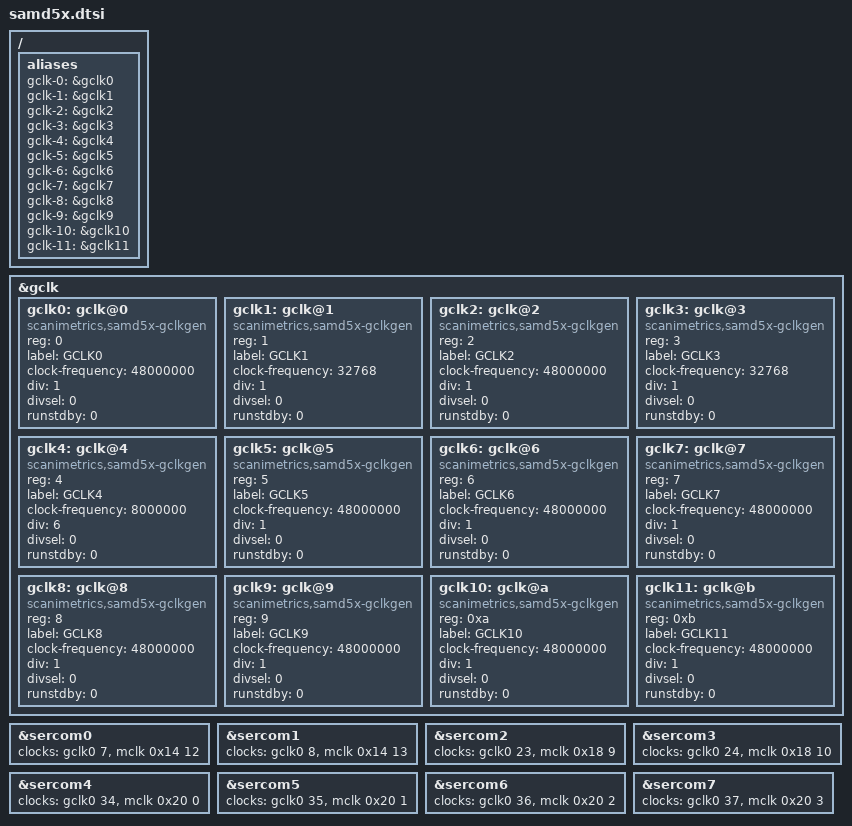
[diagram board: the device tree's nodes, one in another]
/*
 * Copyright (c) 2020 Scanimetics Inc.
 *
 * SPDX-License-Identifier: Apache-2.0
 */

#include <atmel/samd5x.dtsi>

/ {
	aliases {
		gclk-0 = &gclk0;
		gclk-1 = &gclk1;
		gclk-2 = &gclk2;
		gclk-3 = &gclk3;
		gclk-4 = &gclk4;
		gclk-5 = &gclk5;
		gclk-6 = &gclk6;
		gclk-7 = &gclk7;
		gclk-8 = &gclk8;
		gclk-9 = &gclk9;
		gclk-10 = &gclk10;
		gclk-11 = &gclk11;
	};
};

&gclk {
	#address-cells = <1>;
	#size-cells = <0>;

	gclk0: gclk@0 {
		compatible = "scanimetrics,samd5x-gclkgen";
		#clock-cells = <1>;
		reg = <0>;
		label = "GCLK0";
		clock-frequency = <48000000>;
		div = <1>;
		divsel = <0>;
		runstdby = <0>;
	};

	gclk1: gclk@1 {
		compatible = "scanimetrics,samd5x-gclkgen";
		#clock-cells = <1>;
		reg = <1>;
		label = "GCLK1";
		clock-frequency = <32768>;
		div = <1>;
		divsel = <0>;
		runstdby = <0>;
	};

	gclk2: gclk@2 {
		compatible = "scanimetrics,samd5x-gclkgen";
		#clock-cells = <1>;
		reg = <2>;
		label = "GCLK2";
		clock-frequency = <48000000>;
		div = <1>;
		divsel = <0>;
		runstdby = <0>;
	};

	gclk3: gclk@3 {
		compatible = "scanimetrics,samd5x-gclkgen";
		#clock-cells = <1>;
		reg = <3>;
		label = "GCLK3";
		clock-frequency = <32768>;
		div = <1>;
		divsel = <0>;
		runstdby = <0>;
	};

	gclk4: gclk@4 {
		compatible = "scanimetrics,samd5x-gclkgen";
		#clock-cells = <1>;
		reg = <4>;
		label = "GCLK4";
		clock-frequency = <8000000>;
		div = <6>;
		divsel = <0>;
		runstdby = <0>;
	};

	gclk5: gclk@5 {
		compatible = "scanimetrics,samd5x-gclkgen";
		#clock-cells = <1>;
		reg = <5>;
		label = "GCLK5";
		clock-frequency = <48000000>;
		div = <1>;
		divsel = <0>;
		runstdby = <0>;
	};

	gclk6: gclk@6 {
		compatible = "scanimetrics,samd5x-gclkgen";
		#clock-cells = <1>;
		reg = <6>;
		label = "GCLK6";
		clock-frequency = <48000000>;
		div = <1>;
		divsel = <0>;
		runstdby = <0>;
	};

	gclk7: gclk@7 {
		compatible = "scanimetrics,samd5x-gclkgen";
		#clock-cells = <1>;
		reg = <7>;
		label = "GCLK7";
		clock-frequency = <48000000>;
		div = <1>;
		divsel = <0>;
		runstdby = <0>;
	};

	gclk8: gclk@8 {
		compatible = "scanimetrics,samd5x-gclkgen";
		#clock-cells = <1>;
		reg = <8>;
		label = "GCLK8";
		clock-frequency = <48000000>;
		div = <1>;
		divsel = <0>;
		runstdby = <0>;
	};

	gclk9: gclk@9 {
		compatible = "scanimetrics,samd5x-gclkgen";
		#clock-cells = <1>;
		reg = <9>;
		label = "GCLK9";
		clock-frequency = <48000000>;
		div = <1>;
		divsel = <0>;
		runstdby = <0>;
	};

	gclk10: gclk@a {
		compatible = "scanimetrics,samd5x-gclkgen";
		#clock-cells = <1>;
		reg = <0xa>;
		label = "GCLK10";
		clock-frequency = <48000000>;
		div = <1>;
		divsel = <0>;
		runstdby = <0>;
	};

	gclk11: gclk@b {
		compatible = "scanimetrics,samd5x-gclkgen";
		#clock-cells = <1>;
		reg = <0xb>;
		label = "GCLK11";
		clock-frequency = <48000000>;
		div = <1>;
		divsel = <0>;
		runstdby = <0>;
	};
};

&sercom0 {
	clocks = <&gclk0 7>, <&mclk 0x14 12>;
};

&sercom1 {
	clocks = <&gclk0 8>, <&mclk 0x14 13>;
};

&sercom2 {
	clocks = <&gclk0 23>, <&mclk 0x18 9>;
};

&sercom3 {
	clocks = <&gclk0 24>, <&mclk 0x18 10>;
};

&sercom4 {
	clocks = <&gclk0 34>, <&mclk 0x20 0>;
};

&sercom5 {
	clocks = <&gclk0 35>, <&mclk 0x20 1>;
};

&sercom6 {
	clocks = <&gclk0 36>, <&mclk 0x20 2>;
};

&sercom7 {
	clocks = <&gclk0 37>, <&mclk 0x20 3>;
};
